# PRU_ICSS_INTC register map
Vendor: Texas Instruments
Peripheral module from a debugger description file (folder am437x).
Registers are 32-bit, access per field, no defined reset value unless marked. A register's access mark holds for its fields unless they carry their own. Offsets are as the file gives them; lines under a group give offsets from that group; [hi:lo] are bit positions; {n}, {i} and the like mark numbered series; 'fields as' and 'values as' point back to an identical list; <NAME> marks a mode.

## PRU_ICSS_INTC
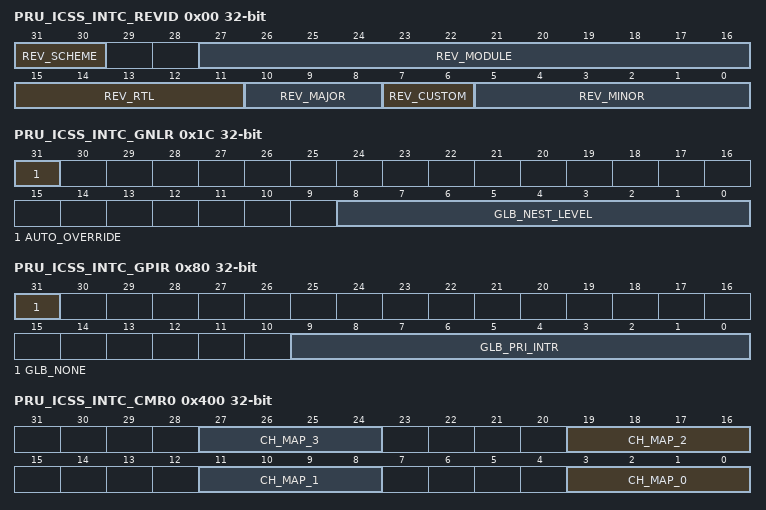
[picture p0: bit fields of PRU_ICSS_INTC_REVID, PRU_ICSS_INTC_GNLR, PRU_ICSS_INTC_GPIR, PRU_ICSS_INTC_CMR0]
0x00 PRU_ICSS_INTC_REVID ro — Revision ID Register
  [31:30] REV_SCHEME — SCHEME
  [27:16] REV_MODULE — MODULE ID
  [15:11] REV_RTL — RTL REVISIONS
  [10:8] REV_MAJOR — MAJOR REVISION
  [7:6] REV_CUSTOM — CUSTOM REVISION
  [5:0] REV_MINOR — MINOR REVISION
0x04 PRU_ICSS_INTC_CR — The Control Register holds global control parameters and can forces a soft reset on the module.
  [3:2] NEST_MODE rw — The nesting mode. 0 = no nesting 1 = automatic individual nesting (per host interrupt) 2 = automatic global nesting (over all host interrupts) 3 = manual nesting
0x10 PRU_ICSS_INTC_GER — The Global Host Interrupt Enable Register enables all the host interrupts. Individual host interrupts are still enabled or disabled from their individual enables and are not overridden by the global enable.
  [0] EN_HINT_ANY rw — The current global enable value when read. Writes set the global enable.
0x1C PRU_ICSS_INTC_GNLR — The Global Nesting Level Register allows the checking and setting of the global nesting level across all host interrupts when automatic global nesting mode is set. The nesting level is the channel (and all of lower priority) that are nested out because of a current interrupt. This register is only available when nesting is configured.
  [31] AUTO_OVERRIDE wo — Always read as 0. Writes of 1 override the automatic nesting and set the nesting_level to the written data.
  [8:0] GLB_NEST_LEVEL rw — The current global nesting level (highest channel that is nested). Writes set the nesting level. In auto nesting mode this value is updated internally unless the auto_override bit is set.
0x20 PRU_ICSS_INTC_SISR — The System Interrupt Status Indexed Set Register allows setting the status of an interrupt. The interrupt to set is the index value written. This sets the Raw Status Register bit of the given index.
  [9:0] STS_SET_IDX wo — Writes set the status of the interrupt given in the index value. Reads return 0.
0x24 PRU_ICSS_INTC_SICR — The System Interrupt Status Indexed Clear Register allows clearing the status of an interrupt. The interrupt to clear is the index value written. This clears the Raw Status Register bit of the given index.
  [9:0] STS_CLR_IDX wo — Writes clear the status of the interrupt given in the index value. Reads return 0.
0x28 PRU_ICSS_INTC_EISR — The System Interrupt Enable Indexed Set Register allows enabling an interrupt. The interrupt to enable is the index value written. This sets the Enable Register bit of the given index.
  [9:0] EN_SET_IDX wo — Writes set the enable of the interrupt given in the index value. Reads return 0.
0x2C PRU_ICSS_INTC_EICR — The System Interrupt Enable Indexed Clear Register allows disabling an interrupt. The interrupt to disable is the index value written. This clears the Enable Register bit of the given index.
  [9:0] EN_CLR_IDX wo — Writes clear the enable of the interrupt given in the index value. Reads return 0.
0x34 PRU_ICSS_INTC_HIEISR — The Host Interrupt Enable Indexed Set Register allows enabling a host interrupt output. The host interrupt to enable is the index value written. This enables the host interrupt output or triggers the output again if already enabled.
  [9:0] HINT_EN_SET_IDX rw — Writes set the enable of the host interrupt given in the index value. Reads return 0.
0x38 PRU_ICSS_INTC_HIDISR — The Host Interrupt Enable Indexed Clear Register allows disabling a host interrupt output. The host interrupt to disable is the index value written. This disables the host interrupt output.
  [9:0] HINT_EN_CLR_IDX rw — Writes clear the enable of the host interrupt given in the index value. Reads return 0.
0x80 PRU_ICSS_INTC_GPIR ro — The Global Prioritized Index Register shows the interrupt number of the highest priority interrupt pending across all the host interrupts.
  [31] GLB_NONE — No Interrupt is pending. Can be used by host to test for a negative value to see if no interrupts are pending.
  [9:0] GLB_PRI_INTR — The currently highest priority interrupt index pending across all the host interrupts.
0x200 PRU_ICSS_INTC_SRSR0 rw — The System Interrupt Status Raw/Set Register0 show the pending enabled status of the system interrupts 0 to 31. Software can write to the Status Set Registers to set a system interrupt without a hardware trigger. There is one bit per system interrupt.
  [31:0] RAW_STS_31_0 — System interrupt raw status and setting of the system interrupts 0 to 31. Reads return the raw status. Write a 1 in a bit position to set the status of the system interrupt. Writing a 0 has no effect.
0x204 PRU_ICSS_INTC_SRSR1 rw — The System Interrupt Status Raw/Set Register1 show the pending enabled status of the system interrupts 32 to 63. Software can write to the Status Set Registers to set a system interrupt without a hardware trigger. There is one bit per system interrupt.
  [31:0] RAW_STS_63_32 — System interrupt raw status and setting of the system interrupts 32 to 63. Reads return the raw status. Write a 1 in a bit position to set the status of the system interrupt. Writing a 0 has no effect.
0x280 PRU_ICSS_INTC_SECR0 rw — The System Interrupt Status Enabled/Clear Register0 show the pending enabled status of the system interrupts 0 to 31. Software can write to the Status Clear Registers to clear a system interrupt after it has been serviced. If a system interrupt status is not cleared then another host interrupt may not be triggered or another host interrupt may be triggered incorrectly. There is one bit per system interrupt.
  [31:0] ENA_STS_31_0 — System interrupt enabled status and clearing of the system interrupts 0 to 31. Reads return the enabled status (before enabling with the Enable Registers). Write a 1 in a bit position to clear the status of the system interrupt. Writing a 0 has no effect.
0x284 PRU_ICSS_INTC_SECR1 rw — The System Interrupt Status Enabled/Clear Register1 show the pending enabled status of the system interrupts 32 to 63. Software can write to the Status Clear Registers to clear a system interrupt after it has been serviced. If a system interrupt status is not cleared then another host interrupt may not be triggered or another host interrupt may be triggered incorrectly. There is one bit per system interrupt.
  [31:0] ENA_STS_63_32 — System interrupt enabled status and clearing of the system interrupts 32 to 63. Reads return the enabled status (before enabling with the Enable Registers). Write a 1 in a bit position to clear the status of the system interrupt. Writing a 0 has no effect.
0x300 PRU_ICSS_INTC_ESR0 access not given — The System Interrupt Enable Set Register0 enables system interrupts 0 to 31 to trigger outputs. System interrupts that are not enabled do not interrupt the host. There is a bit per system interrupt.
  [31:0] EN_SET_31_0 — System interrupt enables system interrupts 0 to 31. Read returns the enable value ( 0 = disabled, 1 = enabled). Write a 1 in a bit position to set that enable. Writing a 0 has no effect.
0x304 PRU_ICSS_INTC_ESR1 access not given — The System Interrupt Enable Set Register1 enables system interrupts 32 to 63 to trigger outputs. System interrupts that are not enabled do not interrupt the host. There is a bit per system interrupt.
  [31:0] EN_SET_63_32 — System interrupt enables system interrupts 32 to 63. Read returns the enable value ( 0 = disabled, 1 = enabled). Write a 1 in a bit position to set that enable. Writing a 0 has no effect.
0x380 PRU_ICSS_INTC_ECR0 access not given — The System Interrupt Enable Clear Register0 disables system interrupts 0 to 31 to map to channels. System interrupts that are not enabled do not interrupt the host. There is a bit per system interrupt.
  [31:0] EN_CLR_31_0 — System interrupt enables system interrupts 0 to 31. Read returns the enable value ( 0 = disabled, 1 = enabled). Write a 1 in a bit position to clear that enable. Writing a 0 has no effect.
0x384 PRU_ICSS_INTC_ECR1 access not given — The System Interrupt Enable Clear Register1 disables system interrupts 32 to 63 to map to channels. System interrupts that are not enabled do not interrupt the host. There is a bit per system interrupt.
  [31:0] EN_CLR_63_32 — System interrupt enables system interrupts 32 to 63. Read returns the enable value ( 0 = disabled, 1 = enabled). Write a 1 in a bit position to clear that enable. Writing a 0 has no effect.
0x400 PRU_ICSS_INTC_CMR0 — The Channel Map Register0 specify the channel for the system interrupts 0 to 3. There is one register per 4 system interrupts.
  [8n+3:8n] CH_MAP_{n} rw (n=0..3) — Sets the channel for the system interrupt {n}
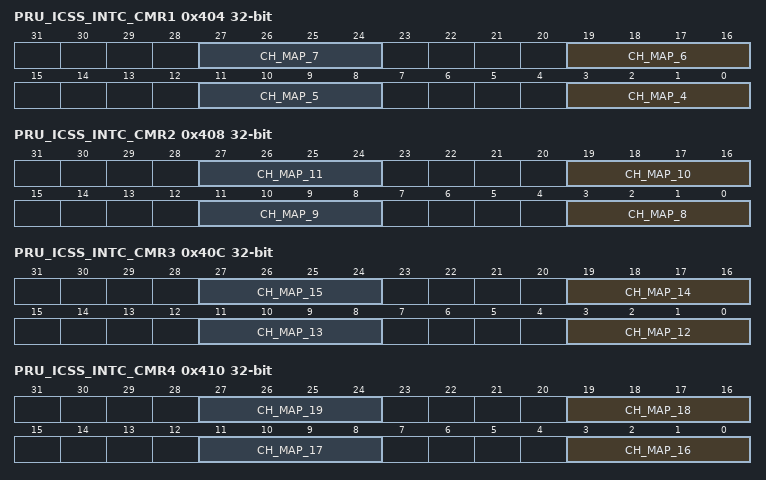
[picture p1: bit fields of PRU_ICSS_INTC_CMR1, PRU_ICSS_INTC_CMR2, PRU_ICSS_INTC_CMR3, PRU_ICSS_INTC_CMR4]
0x404 PRU_ICSS_INTC_CMR1 — The Channel Map Register1 specify the channel for the system interrupts 4 to 7. There is one register per 4 system interrupts.
  [8n-29:8n-32] CH_MAP_{n} rw (n=4..7) — Sets the channel for the system interrupt {n}
0x408 PRU_ICSS_INTC_CMR2 — The Channel Map Register2 specify the channel for the system interrupts 8 to 11. There is one register per 4 system interrupts.
  [8n-61:8n-64] CH_MAP_{n} rw (n=8..11) — Sets the channel for the system interrupt {n}
0x40C PRU_ICSS_INTC_CMR3 — The Channel Map Register3 specify the channel for the system interrupts 12 to 15. There is one register per 4 system interrupts.
  [8n-93:8n-96] CH_MAP_{n} rw (n=12..15) — Sets the channel for the system interrupt {n}
0x410 PRU_ICSS_INTC_CMR4 — The Channel Map Register4 specify the channel for the system interrupts 16 to 19. There is one register per 4 system interrupts.
  [8n-125:8n-128] CH_MAP_{n} rw (n=16..19) — Sets the channel for the system interrupt {n}
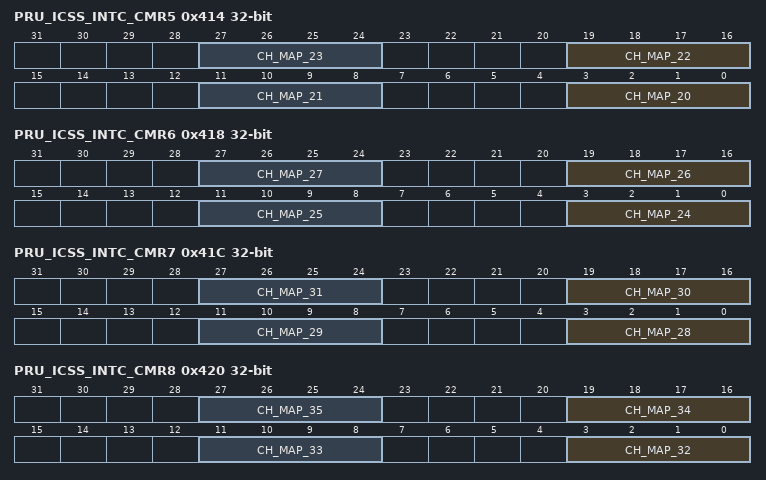
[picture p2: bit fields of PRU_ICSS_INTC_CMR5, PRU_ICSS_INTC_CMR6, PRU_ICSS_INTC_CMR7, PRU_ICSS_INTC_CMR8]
0x414 PRU_ICSS_INTC_CMR5 — The Channel Map Register5 specify the channel for the system interrupts 20 to 23. There is one register per 4 system interrupts.
  [8n-157:8n-160] CH_MAP_{n} rw (n=20..23) — Sets the channel for the system interrupt {n}
0x418 PRU_ICSS_INTC_CMR6 — The Channel Map Register6 specify the channel for the system interrupts 24 to 27. There is one register per 4 system interrupts.
  [8n-189:8n-192] CH_MAP_{n} rw (n=24..27) — Sets the channel for the system interrupt {n}
0x41C PRU_ICSS_INTC_CMR7 — The Channel Map Register7 specify the channel for the system interrupts 28 to 31. There is one register per 4 system interrupts.
  [8n-221:8n-224] CH_MAP_{n} rw (n=28..31) — Sets the channel for the system interrupt {n}
0x420 PRU_ICSS_INTC_CMR8 — The Channel Map Register8 specify the channel for the system interrupts 32 to 35. There is one register per 4 system interrupts.
  [8n-253:8n-256] CH_MAP_{n} rw (n=32..35) — Sets the channel for the system interrupt {n}
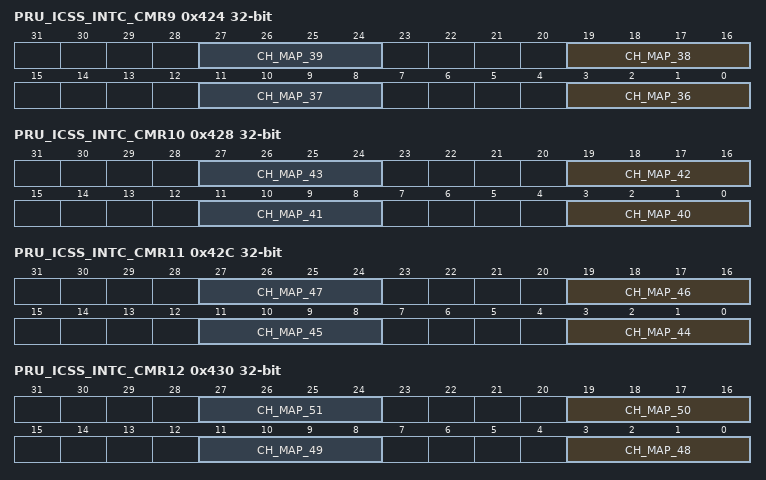
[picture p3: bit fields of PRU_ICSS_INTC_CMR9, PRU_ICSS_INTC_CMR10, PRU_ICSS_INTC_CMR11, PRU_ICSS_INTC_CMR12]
0x424 PRU_ICSS_INTC_CMR9 — The Channel Map Register9 specify the channel for the system interrupts 36 to 39. There is one register per 4 system interrupts.
  [8n-285:8n-288] CH_MAP_{n} rw (n=36..39) — Sets the channel for the system interrupt {n}
0x428 PRU_ICSS_INTC_CMR10 — The Channel Map Register10 specify the channel for the system interrupts 40 to 43. There is one register per 4 system interrupts.
  [8n-317:8n-320] CH_MAP_{n} rw (n=40..43) — Sets the channel for the system interrupt {n}
0x42C PRU_ICSS_INTC_CMR11 — The Channel Map Register11 specify the channel for the system interrupts 44 to 47. There is one register per 4 system interrupts.
  [8n-349:8n-352] CH_MAP_{n} rw (n=44..47) — Sets the channel for the system interrupt {n}
0x430 PRU_ICSS_INTC_CMR12 — The Channel Map Register12 specify the channel for the system interrupts 48 to 51. There is one register per 4 system interrupts.
  [8n-381:8n-384] CH_MAP_{n} rw (n=48..51) — Sets the channel for the system interrupt {n}
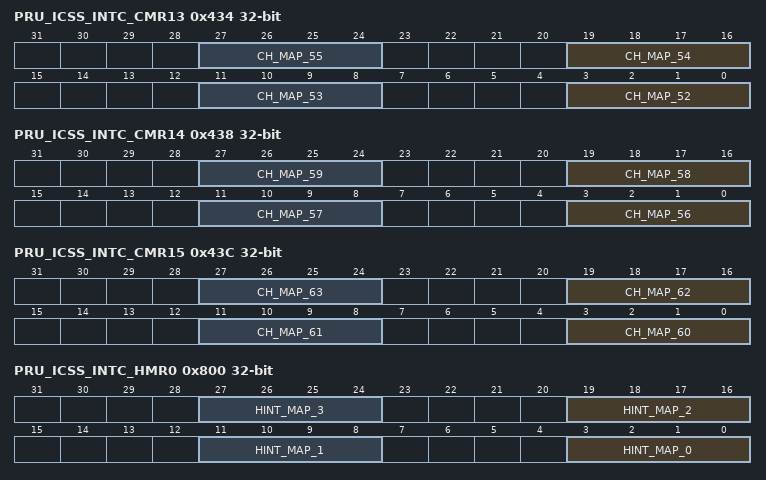
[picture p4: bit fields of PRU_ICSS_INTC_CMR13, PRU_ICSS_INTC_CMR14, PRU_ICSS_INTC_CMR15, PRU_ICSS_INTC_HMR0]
0x434 PRU_ICSS_INTC_CMR13 — The Channel Map Register13 specify the channel for the system interrupts 52 to 55. There is one register per 4 system interrupts.
  [8n-413:8n-416] CH_MAP_{n} rw (n=52..55) — Sets the channel for the system interrupt {n}
0x438 PRU_ICSS_INTC_CMR14 — The Channel Map Register14 specify the channel for the system interrupts 56 to 59. There is one register per 4 system interrupts.
  [8n-445:8n-448] CH_MAP_{n} rw (n=56..59) — Sets the channel for the system interrupt {n}
0x43C PRU_ICSS_INTC_CMR15 — The Channel Map Register15 specify the channel for the system interrupts 60 to 63. There is one register per 4 system interrupts.
  [8n-477:8n-480] CH_MAP_{n} rw (n=60..63) — Sets the channel for the system interrupt {n}
0x800 PRU_ICSS_INTC_HMR0 — The Host Interrupt Map Register0 define the host interrupt for channels 0 to 3. There is one register per 4 channels. Channels with forced host interrupt mappings will have their fields read-only.
  [8n+3:8n] HINT_MAP_{n} rw (n=0..3) — HOST INTERRUPT MAP FOR CHANNEL {n}
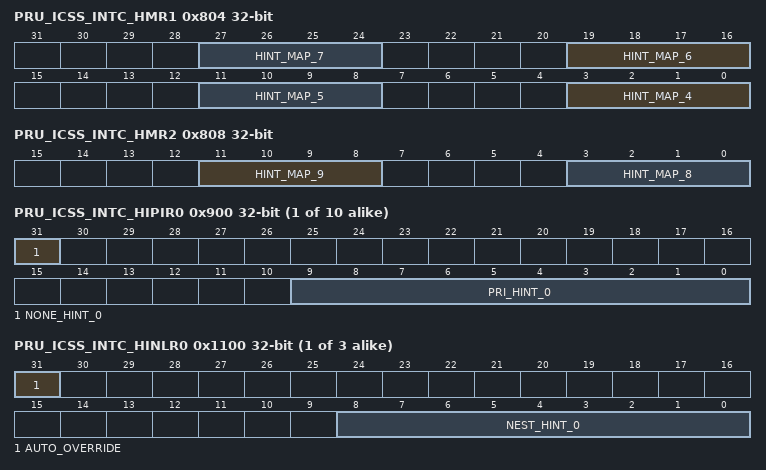
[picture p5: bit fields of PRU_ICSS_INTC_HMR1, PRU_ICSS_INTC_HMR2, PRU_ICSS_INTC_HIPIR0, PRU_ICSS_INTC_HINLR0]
0x804 PRU_ICSS_INTC_HMR1 — The Host Interrupt Map Register1 define the host interrupt for channels 4 to 7. There is one register per 4 channels. Channels with forced host interrupt mappings will have their fields read-only.
  [8n-29:8n-32] HINT_MAP_{n} rw (n=4..7) — HOST INTERRUPT MAP FOR CHANNEL {n}
0x808 PRU_ICSS_INTC_HMR2 — The Host Interrupt Map Register2 define the host interrupt for channels 8 to 9. There is one register per 4 channels. Channels with forced host interrupt mappings will have their fields read-only.
  [11:8] HINT_MAP_9 rw — HOST INTERRUPT MAP FOR CHANNEL 9
  [3:0] HINT_MAP_8 rw — HOST INTERRUPT MAP FOR CHANNEL 8
{0x900+4i} PRU_ICSS_INTC_HIPIR{i} ro (i=0..9) — The Host Interrupt Prioritized Index Register{i} shows the highest priority current pending interrupt for the host interrupt {i}. There is one register per host interrupt.
  [31] NONE_HINT_{i} — No pending interrupt.
  [9:0] PRI_HINT_{i} — HOST INT {i} PRIORITIZED INTERRUPT. Interrupt number of the highest priority pending interrupt for this host interrupt.
0xD00 PRU_ICSS_INTC_SIPR0 rw — The System Interrupt Polarity Register0 define the polarity of the system interrupts 0 to 31. There is a polarity for each system interrupt. The polarity of all system interrupts is active high; always write 1 to the bits of this register.
  [31:0] POLARITY_31_0 — Interrupt polarity of the system interrupts 0 to 31. 0 = active low. 1 = active high.
0xD04 PRU_ICSS_INTC_SIPR1 rw — The System Interrupt Polarity Register1 define the polarity of the system interrupts 32 to 63. There is a polarity for each system interrupt. The polarity of all system interrupts is active high; always write 1 to the bits of this register.
  [31:0] POLARITY_63_32 — Interrupt polarity of the system interrupts 32 to 63. 0 = active low. 1 = active high.
0xD80 PRU_ICSS_INTC_SITR0 rw — The System Interrupt Type Register0 define the type of the system interrupts 0 to 31. There is a type for each system interrupt. The type of all system interrupts is pulse; always write 0 to the bits of this register.
  [31:0] TYPE_31_0 — Interrupt type of the system interrupts 0 to 31. 0 = level or pulse interrupt. 1 = edge interrupt (required edge detect).
0xD84 PRU_ICSS_INTC_SITR1 rw — The System Interrupt Type Register1 define the type of the system interrupts 32 to 63. There is a type for each system interrupt. The type of all system interrupts is pulse; always write 0 to the bits of this register.
  [31:0] TYPE_63_32 — Interrupt type of the system interrupts 32 to 63. 0 = level or pulse interrupt. 1 = edge interrupt (required edge detect).
{0x1100+4i} PRU_ICSS_INTC_HINLR{i} (i=0..2) — The Host Interrupt Nesting Level Register{i} display and control the nesting level for host interrupt {i}. The nesting level controls which channel and lower priority channels are nested. There is one register per host interrupt.
  [31] AUTO_OVERRIDE wo — Reads return 0. Writes of a 1 override the auto updating of the nesting_level and use the write data.
  [8:0] NEST_HINT_{i} rw — Reads return the current nesting level for the host interrupt. Writes set the nesting level for the host interrupt. In auto mode the value is updated internally unless the auto_override is set and then the write data is used.
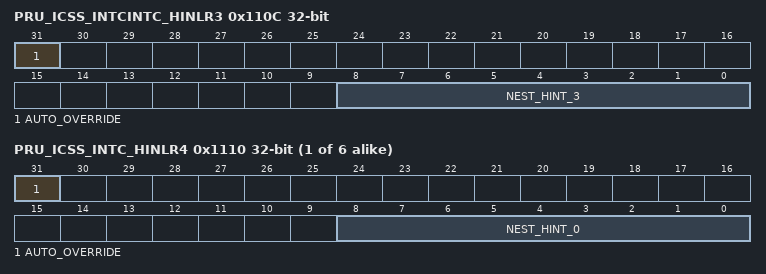
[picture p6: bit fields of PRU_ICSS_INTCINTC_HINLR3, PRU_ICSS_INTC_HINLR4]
0x110C PRU_ICSS_INTCINTC_HINLR3 — The Host Interrupt Nesting Level Register3 display and control the nesting level for host interrupt 3. The nesting level controls which channel and lower priority channels are nested. There is one register per host interrupt.
  [31] AUTO_OVERRIDE wo — Reads return 0. Writes of a 1 override the auto updating of the nesting_level and use the write data.
  [8:0] NEST_HINT_3 rw — Reads return the current nesting level for the host interrupt. Writes set the nesting level for the host interrupt. In auto mode the value is updated internally unless the auto_override is set and then the write data is used.
{0x1100+4i} PRU_ICSS_INTC_HINLR{i} (i=4..9) — The Host Interrupt Nesting Level Register{i} display and control the nesting level for host interrupt {i}. The nesting level controls which channel and lower priority channels are nested. There is one register per host interrupt.
  fields as PRU_ICSS_INTC_HINLR0
0x1500 PRU_ICSS_INTC_HIER — The Host Interrupt Enable Registers enable or disable individual host interrupts. These work separately from the global enables. There is one bit per host interrupt. These bits are updated when writing to the Host Interrupt Enable Index Set and Host Interrupt Enable Index Clear registers.
  [9:0] EN_HINT rw — The enable of the host interrupts (one per bit). 0 = disabled 1 = enabled
